# STM32F101C4T6 register map
File version: 1.0
Registers are 32-bit, access not given, reset 0x0 unless marked. A register's access mark holds for its fields unless they carry their own. Offsets are from the block's base; [hi:lo] are bit positions; {n}, {i} and the like mark numbered series; 'fields as' and 'values as' point back to an identical list.

## DMA1
Base 0x40020000
Same registers: DMA2 0x40020400
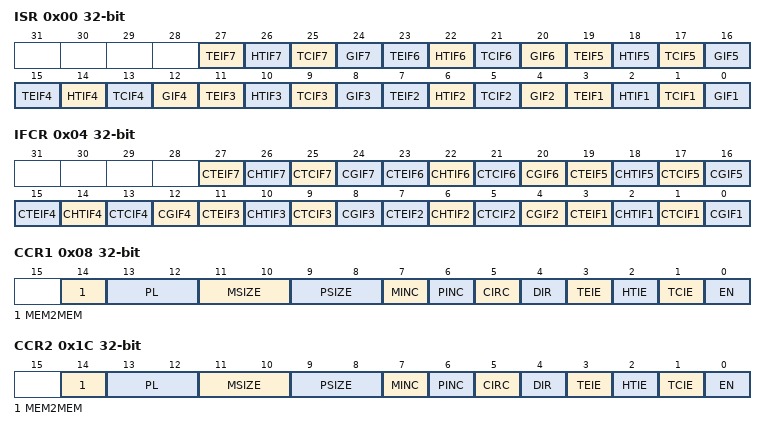
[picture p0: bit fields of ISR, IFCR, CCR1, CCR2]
0x00 ISR
  [4n-1] TEIF{n} (n=1..7), [4n-2] HTIF{n} (n=1..7), [4n-3] TCIF{n} (n=1..7), [4n-4] GIF{n} (n=1..7)
0x04 IFCR
  [4n-1] CTEIF{n} (n=1..7), [4n-2] CHTIF{n} (n=1..7), [4n-3] CTCIF{n} (n=1..7), [4n-4] CGIF{n} (n=1..7)
0x08 CCR1
  [14] MEM2MEM, [13:12] PL, [11:10] MSIZE, [9:8] PSIZE, [7] MINC, [6] PINC, [5] CIRC, [4] DIR, [3] TEIE, [2] HTIE, [1] TCIE, [0] EN
0x0C CNDTR1
  [15:0] NDT
0x10 CPAR1
  [31:0] PA
{0x0+0x14*i} CMAR{i} (i=1..7)
  [31:0] MA
0x1C CCR2
  fields as CCR1
0x20 CNDTR2
  [15:0] NDT
0x24 CPAR2
  [31:0] PA
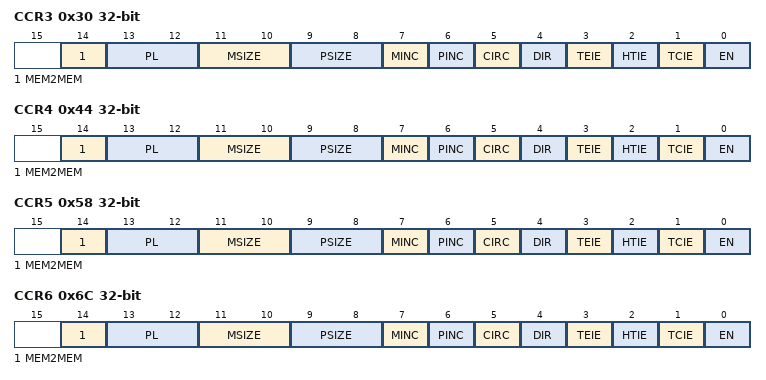
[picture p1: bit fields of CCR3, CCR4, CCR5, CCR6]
0x30 CCR3
  fields as CCR1
0x34 CNDTR3
  [15:0] NDT
0x38 CPAR3
  [31:0] PA
0x44 CCR4
  fields as CCR1
0x48 CNDTR4
  [15:0] NDT
0x4C CPAR4
  [31:0] PA
0x58 CCR5
  fields as CCR1
0x5C CNDTR5
  [15:0] NDT
0x60 CPAR5
  [31:0] PA
0x6C CCR6
  fields as CCR1
0x70 CNDTR6
  [15:0] NDT
0x74 CPAR6
  [31:0] PA
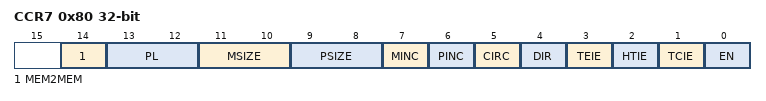
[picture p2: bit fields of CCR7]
0x80 CCR7
  fields as CCR1
0x84 CNDTR7
  [15:0] NDT
0x88 CPAR7
  [31:0] PA

## RCC
Base 0x40021000
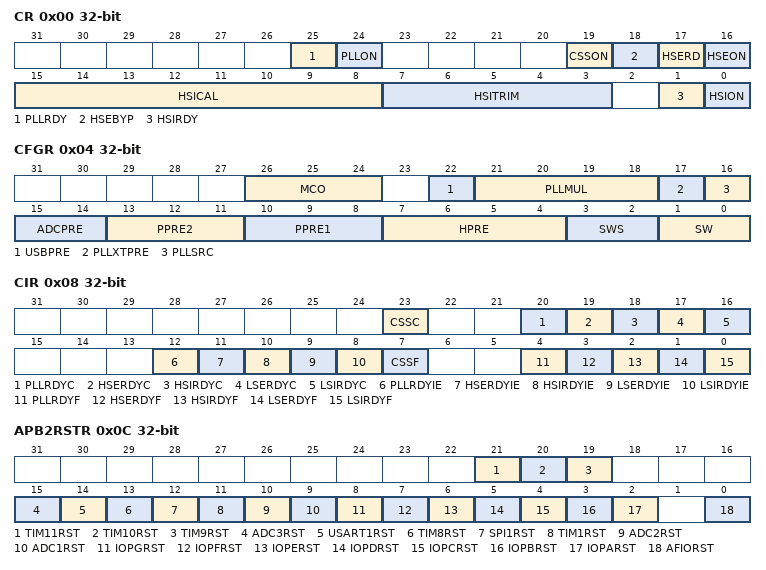
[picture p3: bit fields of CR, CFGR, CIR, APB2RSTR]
0x00 CR
  [25] PLLRDY, [24] PLLON, [19] CSSON, [18] HSEBYP, [17] HSERD, [16] HSEON, [15:8] HSICAL, [7:3] HSITRIM, [1] HSIRDY, [0] HSION
0x04 CFGR
  [26:24] MCO, [22] USBPRE, [21:18] PLLMUL, [17] PLLXTPRE, [16] PLLSRC, [15:14] ADCPRE, [13:11] PPRE2, [10:8] PPRE1, [7:4] HPRE, [3:2] SWS, [1:0] SW
0x08 CIR
  [23] CSSC, [20] PLLRDYC, [19] HSERDYC, [18] HSIRDYC, [17] LSERDYC, [16] LSIRDYC, [12] PLLRDYIE, [11] HSERDYIE, [10] HSIRDYIE, [9] LSERDYIE, [8] LSIRDYIE, [7] CSSF, [4] PLLRDYF, [3] HSERDYF, [2] HSIRDYF, [1] LSERDYF, [0] LSIRDYF
0x0C APB2RSTR
  [21] TIM11RST, [20] TIM10RST, [19] TIM9RST, [15] ADC3RST, [14] USART1RST, [13] TIM8RST, [12] SPI1RST, [11] TIM1RST, [10] ADC2RST, [9] ADC1RST, [8] IOPGRST, [7] IOPFRST, [6] IOPERST, [5] IOPDRST, [4] IOPCRST, [3] IOPBRST, [2] IOPARST, [0] AFIORST
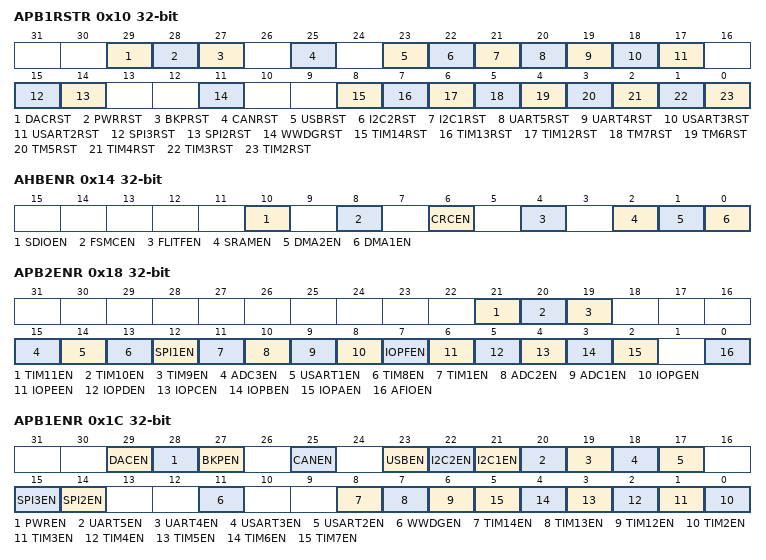
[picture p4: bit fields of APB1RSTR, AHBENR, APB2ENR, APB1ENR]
0x10 APB1RSTR
  [29] DACRST, [28] PWRRST, [27] BKPRST, [25] CANRST, [23] USBRST, [22] I2C2RST, [21] I2C1RST, [20] UART5RST, [19] UART4RST, [18] USART3RST, [17] USART2RST, [15] SPI3RST, [14] SPI2RST, [11] WWDGRST, [8] TIM14RST, [7] TIM13RST, [6] TIM12RST, [5] TM7RST, [4] TM6RST, [3] TM5RST, [2] TIM4RST, [1] TIM3RST, [0] TIM2RST
0x14 AHBENR
  [10] SDIOEN, [8] FSMCEN, [6] CRCEN, [4] FLITFEN, [2] SRAMEN, [1] DMA2EN, [0] DMA1EN
0x18 APB2ENR
  [21] TIM11EN, [20] TIM10EN, [19] TIM9EN, [15] ADC3EN, [14] USART1EN, [13] TIM8EN, [12] SPI1EN, [11] TIM1EN, [10] ADC2EN, [9] ADC1EN, [8] IOPGEN, [7] IOPFEN, [6] IOPEEN, [5] IOPDEN, [4] IOPCEN, [3] IOPBEN, [2] IOPAEN, [0] AFIOEN
0x1C APB1ENR
  [29] DACEN, [28] PWREN, [27] BKPEN, [25] CANEN, [23] USBEN, [22] I2C2EN, [21] I2C1EN, [20] UART5EN, [19] UART4EN, [18] USART3EN, [17] USART2EN, [15] SPI3EN, [14] SPI2EN, [11] WWDGEN, [8] TIM14EN, [7] TIM13EN, [6] TIM12EN, [n-2] TIM{n}EN (n=2..7)
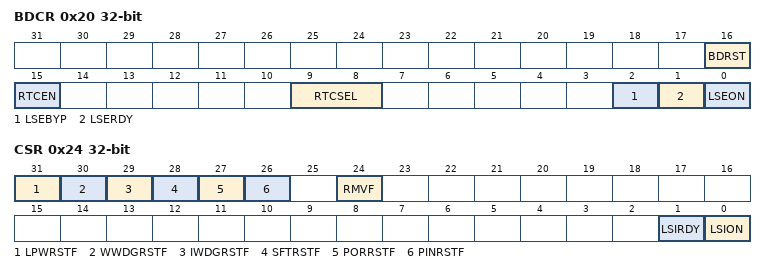
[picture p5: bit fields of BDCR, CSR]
0x20 BDCR
  [16] BDRST, [15] RTCEN, [9:8] RTCSEL, [2] LSEBYP, [1] LSERDY, [0] LSEON
0x24 CSR
  [31] LPWRSTF, [30] WWDGRSTF, [29] IWDGRSTF, [28] SFTRSTF, [27] PORRSTF, [26] PINRSTF, [24] RMVF, [1] LSIRDY, [0] LSION

## CRC
Base 0x40023000
0x00 DR
  [30:0] DATA
0x04 IDR
  [7:0] DATA
0x08 CR
  [0] RESET

## ETH
Base 0x40028000
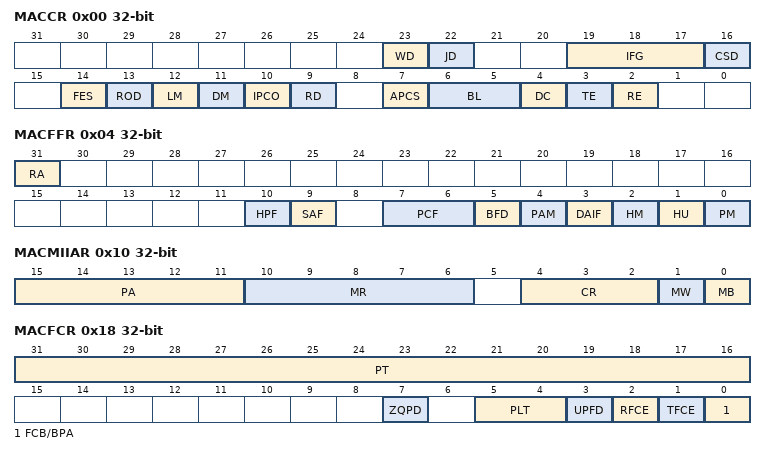
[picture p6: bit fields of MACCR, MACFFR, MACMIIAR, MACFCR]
0x00 MACCR
  [23] WD, [22] JD, [19:17] IFG, [16] CSD, [14] FES, [13] ROD, [12] LM, [11] DM, [10] IPCO, [9] RD, [7] APCS, [6:5] BL, [4] DC, [3] TE, [2] RE
0x04 MACFFR
  [31] RA, [10] HPF, [9] SAF, [7:6] PCF, [5] BFD, [4] PAM, [3] DAIF, [2] HM, [1] HU, [0] PM
0x08 MACHTHR
  [31:0] HTH
0x0C MACHTLR
  [31:0] HTL
0x10 MACMIIAR
  [15:11] PA, [10:6] MR, [4:2] CR, [1] MW, [0] MB
0x14 MACMIIDR
  [15:0] MD
0x18 MACFCR
  [31:16] PT, [7] ZQPD, [5:4] PLT, [3] UPFD, [2] RFCE, [1] TFCE, [0] FCB/BPA
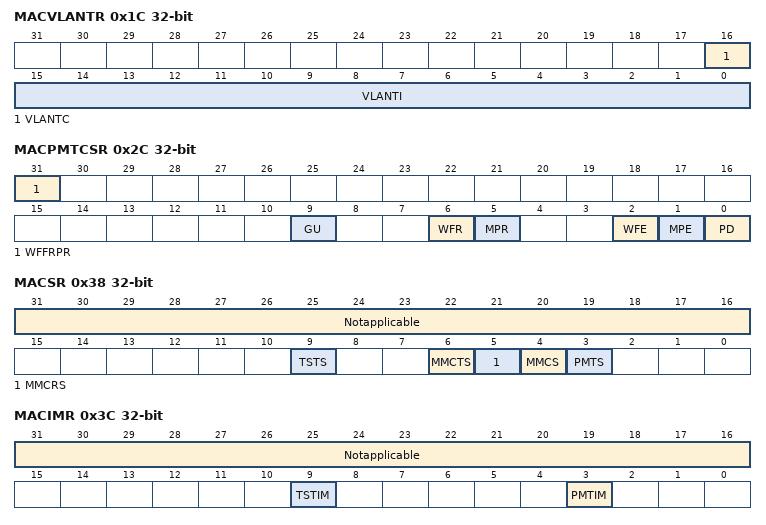
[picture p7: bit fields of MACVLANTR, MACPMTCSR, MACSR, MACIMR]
0x1C MACVLANTR
  [16] VLANTC, [15:0] VLANTI
0x28 MACRWUFFR
  [31:0] FRAME_FILTER_REG
0x2C MACPMTCSR
  [31] WFFRPR, [9] GU, [6] WFR, [5] MPR, [2] WFE, [1] MPE, [0] PD
0x38 MACSR
  [31:16] Notapplicable, [9] TSTS, [6] MMCTS, [5] MMCRS, [4] MMCS, [3] PMTS
0x3C MACIMR
  [31:16] Notapplicable, [9] TSTIM, [3] PMTIM
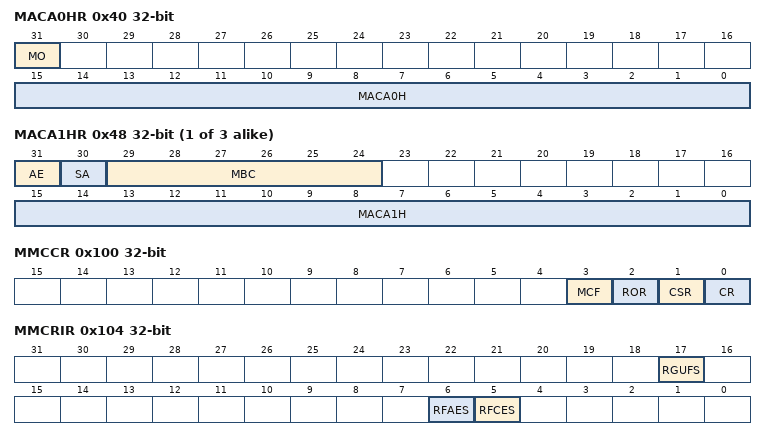
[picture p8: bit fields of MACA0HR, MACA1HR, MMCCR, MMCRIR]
0x40 MACA0HR
  [31] MO, [15:0] MACA0H
{0x44+8i} MACA{i}LR (i=0..3)
  [31:0] MACA{i}L
{0x40+8i} MACA{i}HR (i=1..3)
  [31] AE, [30] SA, [29:24] MBC, [15:0] MACA{i}H
0x100 MMCCR
  [3] MCF, [2] ROR, [1] CSR, [0] CR
0x104 MMCRIR
  [17] RGUFS, [6] RFAES, [5] RFCES
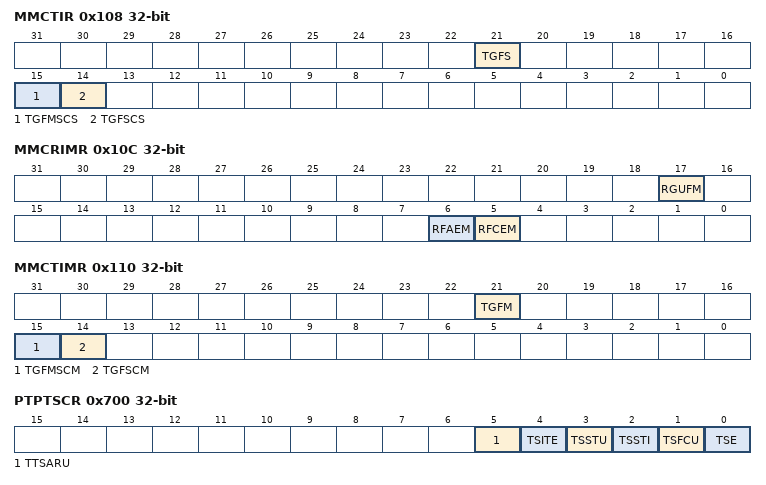
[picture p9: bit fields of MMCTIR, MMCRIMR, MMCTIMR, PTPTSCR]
0x108 MMCTIR
  [21] TGFS, [15] TGFMSCS, [14] TGFSCS
0x10C MMCRIMR
  [17] RGUFM, [6] RFAEM, [5] RFCEM
0x110 MMCTIMR
  [21] TGFM, [15] TGFMSCM, [14] TGFSCM
0x14C MMCTGFSCCR
  [31:0] TGFSCC
0x150 MMCTGFMSCCR
  [31:0] TGFMSCC
0x168 MMCTGFCR
  [31:0] TGFC
0x194 MMCRFCECR
  [31:0] RFCEC
0x198 MMCRFAECR
  [31:0] RFAEC
0x1C4 MMCRGUFCR
  [31:0] RGUFC
0x700 PTPTSCR
  [5] TTSARU, [4] TSITE, [3] TSSTU, [2] TSSTI, [1] TSFCU, [0] TSE
0x704 PTPSSIR
  [7:0] STSSI
0x708 PTPTSHR
  [31:0] STS
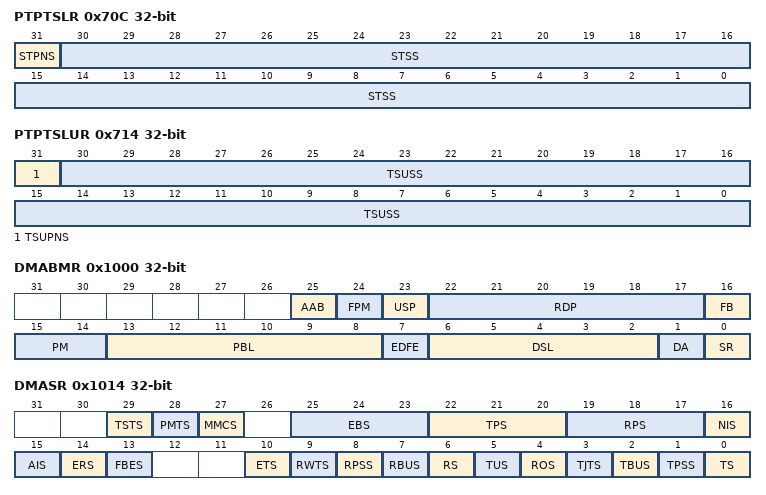
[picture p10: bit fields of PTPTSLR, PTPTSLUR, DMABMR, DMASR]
0x70C PTPTSLR
  [31] STPNS, [30:0] STSS
0x710 PTPTSHUR
  [31:0] TSUS
0x714 PTPTSLUR
  [31] TSUPNS, [30:0] TSUSS
0x718 PTPTSAR
  [31:0] TSA
0x71C PTPTTHR
  [31:0] TTSH
0x720 PTPTTLR
  [31:0] TTSL
0x1000 DMABMR
  [25] AAB, [24] FPM, [23] USP, [22:17] RDP, [16] FB, [15:14] PM, [13:8] PBL, [7] EDFE, [6:2] DSL, [1] DA, [0] SR
0x1004 DMATPDR
  [31:0] TPD
0x1008 DMARPDR
  [31:0] RPD
0x100C DMARDLAR
  [31:0] SRL
0x1010 DMATDLAR
  [31:0] STL
0x1014 DMASR
  [29] TSTS, [28] PMTS, [27] MMCS, [25:23] EBS, [22:20] TPS, [19:17] RPS, [16] NIS, [15] AIS, [14] ERS, [13] FBES, [10] ETS, [9] RWTS, [8] RPSS, [7] RBUS, [6] RS, [5] TUS, [4] ROS, [3] TJTS, [2] TBUS, [1] TPSS, [0] TS
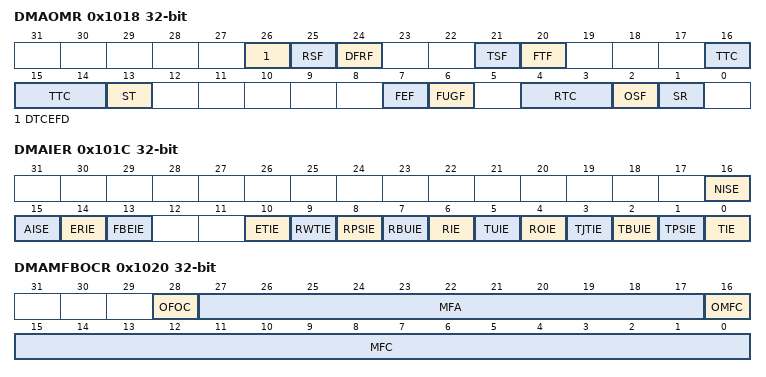
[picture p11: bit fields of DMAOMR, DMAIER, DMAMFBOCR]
0x1018 DMAOMR
  [26] DTCEFD, [25] RSF, [24] DFRF, [21] TSF, [20] FTF, [16:14] TTC, [13] ST, [7] FEF, [6] FUGF, [4:3] RTC, [2] OSF, [1] SR
0x101C DMAIER
  [16] NISE, [15] AISE, [14] ERIE, [13] FBEIE, [10] ETIE, [9] RWTIE, [8] RPSIE, [7] RBUIE, [6] RIE, [5] TUIE, [4] ROIE, [3] TJTIE, [2] TBUIE, [1] TPSIE, [0] TIE
0x1020 DMAMFBOCR
  [28] OFOC, [27:17] MFA, [16] OMFC, [15:0] MFC
0x1048 DMACHTDR
  [31:0] HTDAP
0x104C DMACHRDR
  [31:0] HRDAP
0x1050 DMACHTBAR
  [31:0] HTBAP
0x1054 DMACHRBAR
  [31:0] HRBAP

## FSMC
Base 0xA0000000
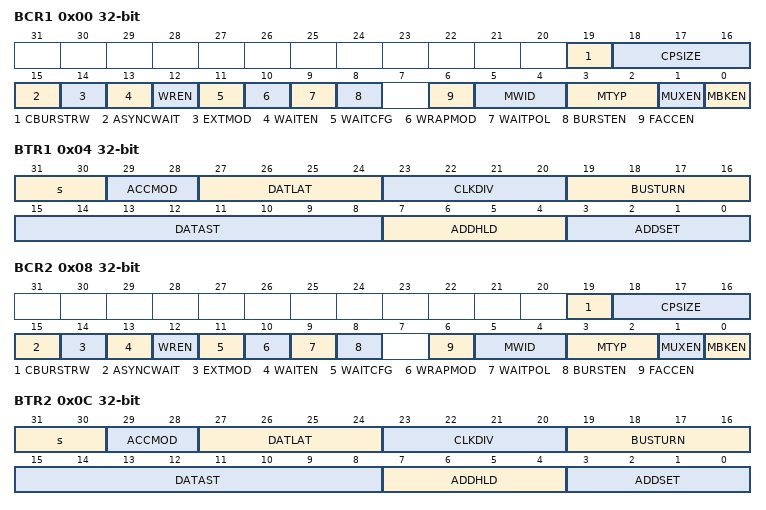
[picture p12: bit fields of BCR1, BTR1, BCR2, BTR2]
0x00 BCR1
  [19] CBURSTRW, [18:16] CPSIZE, [15] ASYNCWAIT, [14] EXTMOD, [13] WAITEN, [12] WREN, [11] WAITCFG, [10] WRAPMOD, [9] WAITPOL, [8] BURSTEN, [6] FACCEN, [5:4] MWID, [3:2] MTYP, [1] MUXEN, [0] MBKEN
0x04 BTR1
  [31:30] s, [29:28] ACCMOD, [27:24] DATLAT, [23:20] CLKDIV, [19:16] BUSTURN, [15:8] DATAST, [7:4] ADDHLD, [3:0] ADDSET
0x08 BCR2
  fields as BCR1
0x0C BTR2
  fields as BTR1
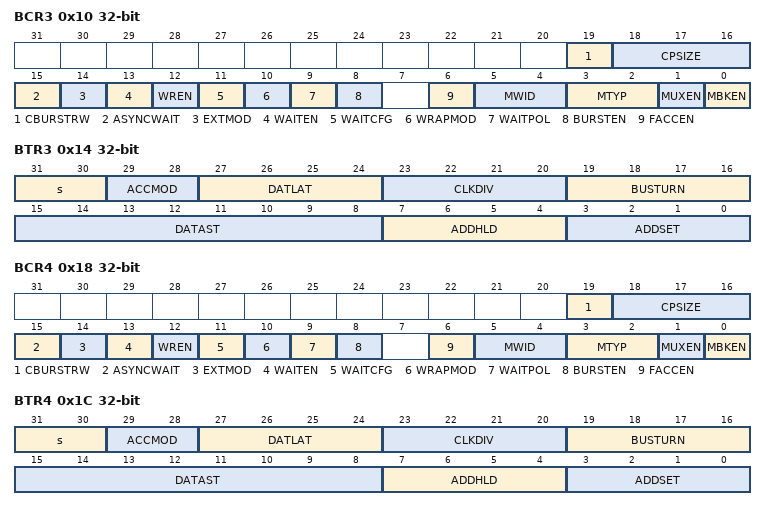
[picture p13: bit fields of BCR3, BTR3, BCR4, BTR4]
0x10 BCR3
  fields as BCR1
0x14 BTR3
  fields as BTR1
0x18 BCR4
  fields as BCR1
0x1C BTR4
  fields as BTR1
{0xFC+8i} BWTR{i} (i=1..4)
  [29:28] ACCMOD, [31:20] s, [19:16] BUSTURN, [15:8] DATAST, [7:4] ADDHLD, [3:0] ADDSET
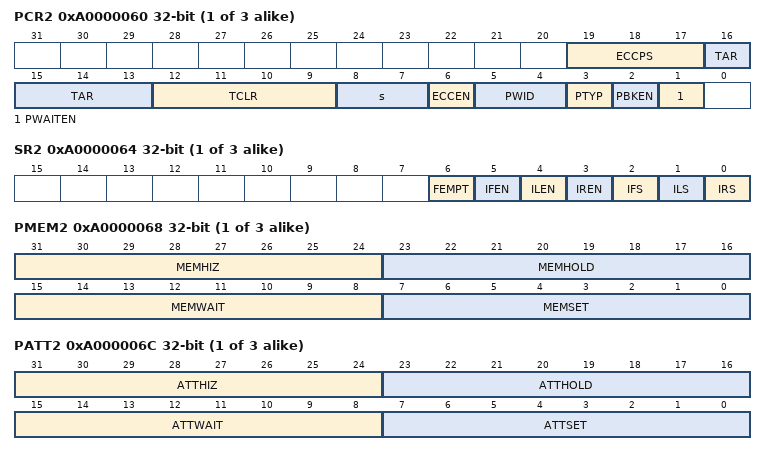
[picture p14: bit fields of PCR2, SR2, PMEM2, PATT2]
{0xA0000020+0x20*i} PCR{i} (i=2..4)
  [19:17] ECCPS, [16:13] TAR, [12:9] TCLR, [8:7] s, [6] ECCEN, [5:4] PWID, [3] PTYP, [2] PBKEN, [1] PWAITEN
{0xA0000024+0x20*i} SR{i} (i=2..4)
  [6] FEMPT, [5] IFEN, [4] ILEN, [3] IREN, [2] IFS, [1] ILS, [0] IRS
{0xA0000028+0x20*i} PMEM{i} (i=2..4)
  [31:24] MEMHIZ, [23:16] MEMHOLD, [15:8] MEMWAIT, [7:0] MEMSET
{0xA000002C+0x20*i} PATT{i} (i=2..4)
  [31:24] ATTHIZ, [23:16] ATTHOLD, [15:8] ATTWAIT, [7:0] ATTSET
0xA0000074 ECCR2
  [31:0] ECC
0xA0000094 ECCR3
  [31:0] ECC
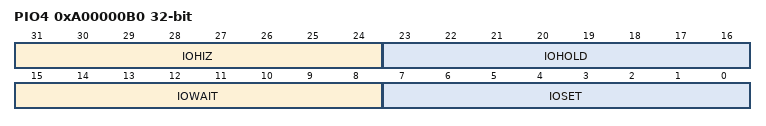
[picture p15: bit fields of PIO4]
0xA00000B0 PIO4
  [31:24] IOHIZ, [23:16] IOHOLD, [15:8] IOWAIT, [7:0] IOSET
